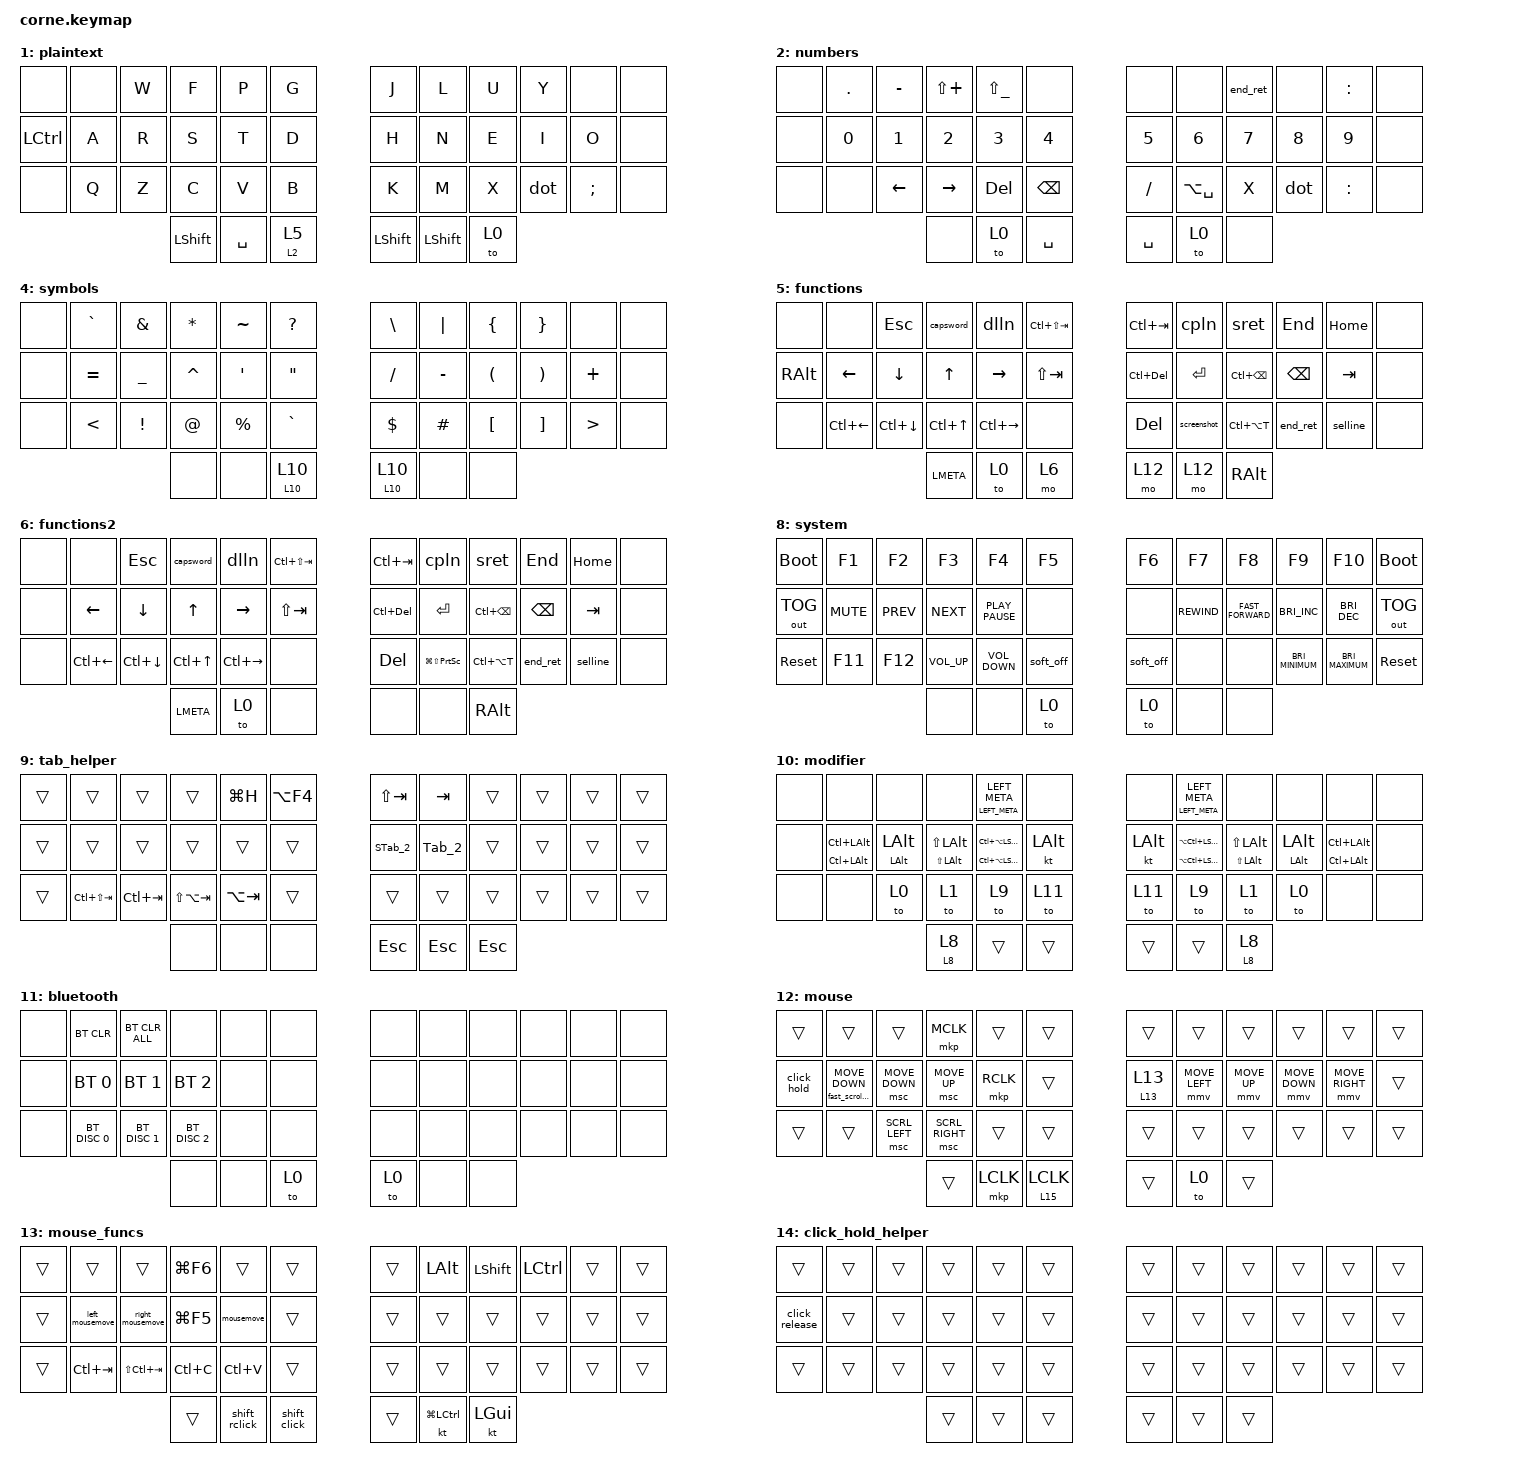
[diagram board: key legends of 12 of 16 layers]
/*
 * Copyright (c) 2020 The ZMK Contributors
 *
 * SPDX-License-Identifier: MIT
 */

#define ZMK_POINTING_DEFAULT_MOVE_VAL 1000  // default: 600
#define ZMK_POINTING_DEFAULT_SCRL_VAL 10   // default: 10

#include <input/processors.dtsi>
#include <behaviors.dtsi>
#include <dt-bindings/zmk/bt.h>
#include <dt-bindings/zmk/keys.h>
#include <dt-bindings/zmk/outputs.h>
#include <dt-bindings/zmk/pointing.h>

#define MAIN 0
#define NAV 1
#define SYM 2
#define FUNC 3
#define FUNC_2 4
#define QWERTY 5

&mmv_input_listener {
    input-processors = <&zip_xy_scaler 1 1>;

    slowMode {
        layers = <14>;
        input-processors = <&zip_xy_scaler 1 2>;
    };
};

/ {
    behaviors {
        dot: dot {
            compatible = "zmk,behavior-tap-dance";
            label = "DOT";
            #binding-cells = <0>;
            bindings = <&kp PERIOD>, <&kp COMMA>;
        };

        ht_lyr: ht_lyr {
            compatible = "zmk,behavior-hold-tap";
            label = "HT_LYR";
            bindings = <&mo>, <&sl>;

            #binding-cells = <2>;
            tapping-term-ms = <160>;
            flavor = "balanced";
            quick-tap-ms = <100>;
        };

        left_hrm: left_hrm {
            compatible = "zmk,behavior-hold-tap";
            label = "LEFT_HRM";
            #binding-cells = <2>;
            flavor = "balanced";
            tapping-term-ms = <160>;
            hold-trigger-key-positions = <6 7 8 9 10 11 18 19 20 21 22 23 30 31 32 33 34 35 39 40 41 36 37 38 0 12 24>;
            bindings = <&kp>, <&kp>;
        };

        right_hrm: right_hrm {
            compatible = "zmk,behavior-hold-tap";
            label = "RIGHT_HRM";
            bindings = <&kp>, <&kp>;

            #binding-cells = <2>;
            tapping-term-ms = <160>;
            flavor = "balanced";
            hold-trigger-key-positions = <0 1 2 3 4 5 12 13 14 15 16 17 24 25 26 27 28 29 36 37 38 39 40 41 11 23 35>;
        };

        left_hrm2: left_hrm2 {
            compatible = "zmk,behavior-hold-tap";
            label = "LEFT_HRM2";
            #binding-cells = <2>;
            flavor = "balanced";
            tapping-term-ms = <145>;
            hold-trigger-key-positions = <6 7 9 10 11 18 19 20 21 22 23 30 31 32 33 34 35 39 40 41 8 36 37 38 0 12 24>;
            bindings = <&mo>, <&kp>;
        };

        right_hrm2: right_hrm2 {
            compatible = "zmk,behavior-hold-tap";
            label = "RIGHT_HRM2";
            bindings = <&mo>, <&kp>;

            #binding-cells = <2>;
            tapping-term-ms = <145>;
            flavor = "balanced";
            hold-trigger-key-positions = <0 1 5 12 13 14 15 16 17 24 25 26 27 28 29 36 37 38 2 3 4 39 40 41 11 23 35>;
            quick-tap-ms = <0>;
        };

        ht_sk: ht_sk {
            compatible = "zmk,behavior-hold-tap";
            label = "HT_SK";
            bindings = <&kp>, <&sk>;

            #binding-cells = <2>;
            tapping-term-ms = <210>;
            flavor = "tap-preferred";
        };

        left_hrm_3: left_hrm_3 {
            compatible = "zmk,behavior-hold-tap";
            label = "LEFT_HRM_3";
            #binding-cells = <2>;
            flavor = "tap-preferred";
            tapping-term-ms = <185>;
            hold-trigger-key-positions = <6 7 8 9 10 11 18 19 20 21 22 23 30 31 32 33 34 35 39 40 41 36 37 38 0 12 24>;
            bindings = <&kp>, <&kp>;

            require-prior-idle-ms = <120>;
            hold-trigger-on-release;
        };

        right_hrm_3: right_hrm_3 {
            compatible = "zmk,behavior-hold-tap";
            label = "RIGHT_HRM_3";
            bindings = <&kp>, <&kp>;

            #binding-cells = <2>;
            tapping-term-ms = <185>;
            flavor = "tap-preferred";
            hold-trigger-key-positions = <0 1 2 3 4 5 12 13 14 15 16 17 24 25 26 27 28 29 36 37 38 39 40 41 11 23 35>;
            require-prior-idle-ms = <120>;
            hold-trigger-on-release;
        };

        caps_word1: caps_word1 {
            compatible = "zmk,behavior-caps-word";
            label = "CAPS_WORD1";
            #binding-cells = <0>;
            continue-list = <F22>;
            mods = <(MOD_LSFT)>;
        };

        ht_k_lyr: ht_k_lyr {
            compatible = "zmk,behavior-hold-tap";
            label = "HT_K_LYR";
            #binding-cells = <2>;
            flavor = "balanced";
            tapping-term-ms = <140>;
            bindings = <&mo>, <&kp>;

            require-prior-idle-ms = <70>;
            hold-trigger-on-release;
        };

        ht_mtab: ht_mtab {
            compatible = "zmk,behavior-hold-tap";
            label = "HT_MTAB";
            bindings = <&ht_lyr_mtab>, <&kp>;

            #binding-cells = <2>;
            tapping-term-ms = <200>;
            flavor = "tap-preferred";
        };

        ht_mkp_lyr: ht_mkp_lyr {
            compatible = "zmk,behavior-hold-tap";
            label = "HT_MKP_LYR";
            #binding-cells = <2>;
            flavor = "balanced";
            tapping-term-ms = <140>;
            bindings = <&mo>, <&mkp>;

            require-prior-idle-ms = <70>;
            hold-trigger-on-release;
        };

        fast_scroll_down: fast_scroll_down {
            compatible = "zmk,behavior-input-two-axis";
            label = "FAST_SCROLL_DOWN";
            #binding-cells = <1>;
            trigger-period-ms = <0>;
            x-input-code = <0>;
            y-input-code = <8>;
            delay-ms = <0>;
            time-to-max-speed-ms = <100>;
        };

        screenshot: screenshot {
            compatible = "zmk,behavior-tap-dance";
            label = "SCREENSHOT";
            #binding-cells = <0>;
            bindings = <&kp LS(LC(PRINTSCREEN))>, <&kp LC(LA(PRINTSCREEN))>;
        };
    };

    macros {
        sret: sret {
            compatible = "zmk,behavior-macro";
            #binding-cells = <0>;
            bindings = <&kp END &kp LS(RET)>;
            label = "SRET";
        };

        af4: af4 {
            compatible = "zmk,behavior-macro";
            #binding-cells = <0>;
            bindings = <&kt LEFT_ALT &kp F4 &kt LEFT_ALT>;
            label = "AF4";
        };

        end_ret: endRet {
            compatible = "zmk,behavior-macro";
            #binding-cells = <0>;
            bindings = <&kp END &kp RET>;
            label = "ENDRET";
        };

        cpln: cpln {
            compatible = "zmk,behavior-macro";
            #binding-cells = <0>;
            bindings = <&kp HOME &kp LS(END) &kp LC(C) &kp END>;
            label = "CPLN";
        };

        dlln: dlln {
            compatible = "zmk,behavior-macro";
            #binding-cells = <0>;
            bindings = <&kp HOME &kp LS(END) &kp DEL>;
            label = "DLLN";
        };

        sw1: sw1 {
            compatible = "zmk,behavior-macro";
            #binding-cells = <0>;
            bindings = <&kp LS(LG(LEFT_ARROW)) &kp LG(LA(H)) &kp LS(LG(RIGHT))>;
            label = "SW1";
        };

        sw2: sw2 {
            compatible = "zmk,behavior-macro";
            #binding-cells = <0>;
            bindings = <&kp LS(LG(RIGHT)) &kp LA(LG(H)) &kp LS(LG(LEFT_ARROW))>;
            label = "SW2";
        };

        capsword: capsword {
            compatible = "zmk,behavior-macro";
            #binding-cells = <0>;
            bindings = <&kp F22 &caps_word1>;
            label = "CAPSWORD";
        };

        on_MTab: on_MTab {
            compatible = "zmk,behavior-macro";
            #binding-cells = <0>;
            bindings = <&kt LEFT_META &tog 9 &kp TAB>;
            label = "ON_MTAB";
        };

        on_MSTab: on_MSTab {
            compatible = "zmk,behavior-macro";
            #binding-cells = <0>;
            bindings = <&kt LEFT_META &tog 9 &kp LS(TAB)>;
            label = "ON_MSTAB";
        };

        STab_2: STab_2 {
            compatible = "zmk,behavior-macro";
            #binding-cells = <0>;
            bindings = <&kp LS(TAB) &kp LS(TAB)>;
            label = "STAB_2";
        };

        Tab_2: Tab_2 {
            compatible = "zmk,behavior-macro";
            #binding-cells = <0>;
            bindings = <&kp TAB &kp TAB>;
            label = "TAB_2";
        };

        selline: selline {
            compatible = "zmk,behavior-macro";
            #binding-cells = <0>;
            bindings = <&kp HOME &kp HOME &kp LS(END) &kp LS(END)>;
            label = "SELLINE";
        };

        dlln2: dlln2 {
            compatible = "zmk,behavior-macro";
            #binding-cells = <0>;
            bindings = <&kp END &kp END &kp LS(LC(BACKSPACE))>;
            label = "DLLN2";
        };

        cut_line: cut_line {
            compatible = "zmk,behavior-macro";
            #binding-cells = <0>;
            bindings = <&kp HOME &kp HOME &kp LS(END) &kp LS(END) &kp LC(X)>;
            label = "CUT_LINE";
        };

        left_mousemove: left_mousemove {
            compatible = "zmk,behavior-macro";
            #binding-cells = <0>;
            bindings = <&kp LS(LG(LC(J))) &kp LG(F5)>;
            label = "LEFT_MOUSEMOVE";
        };

        right_mousemove: right_mousemove {
            compatible = "zmk,behavior-macro";
            #binding-cells = <0>;
            bindings = <&kp LS(LG(LC(H))) &kp LG(F5)>;
            label = "RIGHT_MOUSEMOVE";
        };

        mousemove: mousemove {
            compatible = "zmk,behavior-macro";
            #binding-cells = <0>;
            bindings = <&kp LG(LA(F)) &kp LG(F5)>;
            label = "MOUSEMOVE";
        };

        ht_lyr_mtab: ht_lyr_mtab {
            compatible = "zmk,behavior-macro";
            #binding-cells = <0>;
            bindings =
                <&to 3>,
                <&macro_pause_for_release>,
                <&macro_release>,
                <&kp LEFT_GUI>,
                <&macro_press>,
                <&to 0>;

            label = "HT_LYR_MTAB";
        };

        shift_click: shift_click {
            compatible = "zmk,behavior-macro";
            #binding-cells = <0>;
            bindings =
                <&macro_press>,
                <&kp LSHFT>,
                <&macro_tap>,
                <&mkp LCLK>,
                <&macro_release>,
                <&kp LSHFT>;

            label = "SHIFT_CLICK";
        };

        shift_rclick: shift_rclick {
            compatible = "zmk,behavior-macro";
            #binding-cells = <0>;
            bindings =
                <&macro_press>,
                <&kp LSHFT>,
                <&macro_tap>,
                <&mkp RCLK>,
                <&macro_release>,
                <&kp LSHFT>;

            label = "SHIFT_RCLICK";
        };

        click_hold: click_hold {
            compatible = "zmk,behavior-macro";
            #binding-cells = <0>;
            bindings = <&tog 14>, <&macro_press>, <&mkp LCLK>;

            label = "CLICK_HOLD";
        };

        click_release: click_release {
            compatible = "zmk,behavior-macro";
            #binding-cells = <0>;
            bindings = <&tog 14>, <&macro_release>, <&mkp LCLK>;

            label = "CLICK_RELEASE";
        };

        on_MTab_2: on_Mtab_2 {
            compatible = "zmk,behavior-macro";
            #binding-cells = <0>;
            bindings = <&kt LEFT_META &tog 9 &kp LC(TAB)>;
            label = "ON_MTAB_2";
        };

        on_MSTab_2: on_MSTab_2 {
            compatible = "zmk,behavior-macro";
            #binding-cells = <0>;
            bindings = <&kt LEFT_META &tog 9 &kp LC(LS(TAB))>;
            label = "ON_MSTAB_2";
        };

        on_MTab_3: on_MTab_3 {
            compatible = "zmk,behavior-macro";
            #binding-cells = <0>;
            bindings = <&kt LEFT_META &tog 9 &kp LA(TAB)>;
            label = "ON_MTAB_3";
        };

        on_MSTab_3: on_MSTab_3 {
            compatible = "zmk,behavior-macro";
            #binding-cells = <0>;
            bindings = <&kt LEFT_META &tog 9 &kp LA(LS(TAB))>;
            label = "ON_MSTAB_3";
        };

        moveMonRight: moveMonRight {
            compatible = "zmk,behavior-macro";
            #binding-cells = <0>;
            bindings = <&kp LG(LS(RIGHT))>;
            label = "MOVEMONRIGHT";
        };

        moveMonLeft: moveMonLeft {
            compatible = "zmk,behavior-macro";
            #binding-cells = <0>;
            bindings = <&kp LG(LS(LEFT))>;
            label = "MOVEMONLEFT";
        };

        moveWsNext: moveWsNext {
            compatible = "zmk,behavior-macro";
            #binding-cells = <0>;
            bindings = <&kp LG(LS(LC(RIGHT)))>;
            label = "MOVEWSNEXT";
        };

        moveWsPrev: moveWsPrev {
            compatible = "zmk,behavior-macro";
            #binding-cells = <0>;
            bindings = <&kp LG(LS(LC(LEFT)))>;
            label = "MOVEWSPREV";
        };

        focusWsNext: focusWsNext {
            compatible = "zmk,behavior-macro";
            #binding-cells = <0>;
            bindings = <&kp LC(LG(RIGHT))>;
            label = "FOCUSWSNEXT";
        };

        focusWsPrev: focusWsPrev {
            compatible = "zmk,behavior-macro";
            #binding-cells = <0>;
            bindings = <&kp LC(LG(LEFT))>;
            label = "FOCUSWSPREV";
        };

        focusMonNext: focusMonNext {
            compatible = "zmk,behavior-macro";
            #binding-cells = <0>;
            bindings = <&kp LC(LG(LS(H)))>;
            label = "FOCUSMONNEXT";
        };

        focusMonPrev: focusMonPrev {
            compatible = "zmk,behavior-macro";
            #binding-cells = <0>;
            bindings = <&kp LC(LG(LS(J)))>;
            label = "FOCUSMONPREV";
        };

        cycleFocus: cycleFocus {
            compatible = "zmk,behavior-macro";
            #binding-cells = <0>;
            bindings = <&kp LA(LG(H))>;
            label = "CYCLEFOCUS";
        };

        moveWsUp: moveWsUp {
            compatible = "zmk,behavior-macro";
            #binding-cells = <0>;
            bindings = <&kp LG(LS(LC(UP)))>;
            label = "MOVEWSUP";
        };

        moveWsDown: moveWsDown {
            compatible = "zmk,behavior-macro";
            #binding-cells = <0>;
            bindings = <&kp LG(LS(LC(DOWN)))>;
            label = "MOVEWSDOWN";
        };

        focusWsUp: focusWsUp {
            compatible = "zmk,behavior-macro";
            #binding-cells = <0>;
            bindings = <&kp LC(LG(UP))>;
            label = "FOCUSWSUP";
        };

        focusWsDown: focusWsDown {
            compatible = "zmk,behavior-macro";
            #binding-cells = <0>;
            bindings = <&kp LC(LG(DOWN))>;
            label = "FOCUSWSDOWN";
        };

        overlay: new_macro {
            compatible = "zmk,behavior-macro";
            #binding-cells = <0>;
            bindings =
                <&macro_tap>,
                <&kp LG(LA(O))>,
                <&macro_pause_for_release>,
                <&kp LG(LS(O))>;

            label = "NEW_MACRO";
        };
    };

    combos {
        compatible = "zmk,combos";

        cut {
            bindings = <&cut_line>;
            key-positions = <4 7>;
            layers = <6>;
        };
    };

    keymap {
        compatible = "zmk,keymap";

        default_layer {
            bindings = <
&kp LS(LC(LG(D)))  &none  &kp W           &kp F                &kp P              &kp G          &kp J        &kp L               &kp U                 &kp Y            &none          &kp RCTRL
&overlay           &kp A  &left_hrm2 4 R  &left_hrm_3 LCTRL S  &left_hrm LSHFT T  &kp D          &kp H        &right_hrm LSHFT N  &right_hrm_3 LCTRL E  &right_hrm2 4 I  &kp O          &kp RALT
&kp LEFT_GUI       &kp Q  &kp Z           &kp C                &kp V              &kp B          &kp K        &kp M               &kp X                 &dot             &kp SEMICOLON  &kp LEFT_GUI
                                          &ht_lyr 10 10        &ht_k_lyr 7 SPACE  &ht_lyr 2 5    &ht_lyr 2 5  &ht_mtab 0 SPACE    &ht_lyr 7 7
            >;
        };

        plaintext {
            bindings = <
&none      &none  &kp W  &kp F      &kp P      &kp G          &kp J           &kp L      &kp U  &kp Y  &none          &none
&kp LCTRL  &kp A  &kp R  &kp S      &kp T      &kp D          &kp H           &kp N      &kp E  &kp I  &kp O          &none
&none      &kp Q  &kp Z  &kp C      &kp V      &kp B          &kp K           &kp M      &kp X  &dot   &kp SEMICOLON  &none
                         &kp LSHFT  &kp SPACE  &ht_lyr 2 5    &kp LEFT_SHIFT  &kp LSHFT  &to 0
            >;
        };

        numbers {
            // -----------------------------------------------------------------------------------------
            // |  TAB |  1  |  2  |  3  |  4  |  5  |   |  6  |  7  |  8  |  9  |  0  | BSPC |
            // | BTCLR| BT1 | BT2 | BT3 | BT4 | BT5 |   | LFT | DWN |  UP | RGT |     |      |
            // | SHFT |     |     |     |     |     |   |     |     |     |     |     |      |
            //                    | GUI |     | SPC |   | ENT |     | ALT |

            bindings = <
&none  &kp DOT  &kp MINUS       &kp LS(PLUS)  &kp LS(UNDER)  &none            &none      &none          &end_ret  &none   &kp COLON  &none
&none  &kp N0   &kp N1          &kp N2        &kp N3         &kp N4           &kp N5     &kp N6         &kp N7    &kp N8  &kp N9     &none
&none  &none    &kp LEFT_ARROW  &kp RIGHT     &kp DELETE     &kp BACKSPACE    &kp FSLH   &kp LA(SPACE)  &kp X     &dot    &kp COLON  &none
                                &none         &to 0          &kp SPACE        &kp SPACE  &to 0          &none
            >;
        };

        navigation {
            bindings = <
&none  &none          &kp LG(LC(LS(T)))  &kp LG(LC(LS(Q)))  &kp LG(RET)   &kp LA(F4)    &kp LC(END)  &kp LC(HOME)  &kp LG(H)     &kp LG(F)     &none          &none
&none  &focusMonPrev  &focusMonNext      &kp LG(LA(J))      &cycleFocus   &moveWsUp     &moveWsDown  &focusWsPrev  &focusWsNext  &moveMonLeft  &moveMonRight  &none
&none  &kp LG(N0)     &kp LG(N1)         &focusWsUp         &focusWsDown  &kp LG(F5)    &kp LG(F6)   &moveWsPrev   &moveWsNext   &kp LC(END)   &kp LC(HOME)   &none
                                         &none              &none         &none         &none        &none         &none
            >;
        };

        symbols {
            bindings = <
&none  &kp GRAVE      &kp AMPERSAND    &kp ASTRK  &kp TILDE       &kp QUESTION         &kp BSLH       &kp PIPE   &kp LEFT_BRACE        &kp RIGHT_BRACE        &none             &none
&none  &kp EQUAL      &kp UNDER        &kp CARET  &kp APOSTROPHE  &kp DOUBLE_QUOTES    &kp SLASH      &kp MINUS  &kp LEFT_PARENTHESIS  &kp RIGHT_PARENTHESIS  &kp PLUS          &none
&none  &kp LESS_THAN  &kp EXCLAMATION  &kp AT     &kp PERCENT     &kp GRAVE            &kp DOLLAR     &kp HASH   &kp LBKT              &kp RBKT               &kp GREATER_THAN  &none
                                       &none      &none           &ht_lyr 10 10        &ht_lyr 10 10  &none      &none
            >;
        };

        functions {
            bindings = <
&none     &none         &kp ESC         &capsword     &dlln          &kp LC(LS(TAB))    &kp LC(TAB)     &cpln        &sret          &kp END   &kp HOME  &none
&kp RALT  &kp LEFT      &kp DOWN_ARROW  &kp UP_ARROW  &kp RIGHT      &kp LS(TAB)        &kp LC(DELETE)  &kp RET      &kp LC(BSPC)   &kp BSPC  &kp TAB   &none
&none     &kp LC(LEFT)  &kp LC(DOWN)    &kp LC(UP)    &kp LC(RIGHT)  &none              &kp DELETE      &screenshot  &kp LC(LA(T))  &end_ret  &selline  &none
                                        &kp LMETA     &to 0          &mo 6              &mo 12          &mo 12       &kp RALT
            >;
        };

        functions2 {
            bindings = <
&none  &none         &kp ESC         &capsword     &dlln          &kp LC(LS(TAB))    &kp LC(TAB)  &cpln                    &sret          &kp END   &kp HOME  &none
&none  &kp LEFT      &kp DOWN_ARROW  &kp UP_ARROW  &kp RIGHT      &kp LS(TAB)        &kp LC(DEL)  &kp RET                  &kp LC(BSPC)   &kp BSPC  &kp TAB   &none
&none  &kp LC(LEFT)  &kp LC(DOWN)    &kp LC(UP)    &kp LC(RIGHT)  &none              &kp DELETE   &kp LG(LS(PRINTSCREEN))  &kp LC(LA(T))  &end_ret  &selline  &none
                                     &kp LMETA     &to 0          &none              &none        &none                    &kp RALT
            >;
        };

        in_app_functions {
            bindings = <
&none  &kp LS(LA(LC(F10)))       &kp LS(LA(LC(F1)))        &kp LA(LC(LS(F2)))        &kp LS(LA(LC(F3)))        &kp LS(LA(LC(F4)))          &kp LS(LA(LC(F5)))        &kp LS(LA(LC(F6)))        &kp LS(LA(LC(F7)))     &kp LS(LC(LA(F8)))     &kp LS(LC(LA(F9)))    &none
&none  &kp LS(LC(LA(NUMBER_0)))  &kp LS(LA(LC(NUMBER_1)))  &kp LS(LA(LC(NUMBER_2)))  &kp LS(LC(LA(NUMBER_3)))  &kp LS(LA(LC(NUMBER_4)))    &kp LS(LA(LC(NUMBER_5)))  &kp LS(LC(LA(NUMBER_6)))  &kp LC(LA(LS(N7)))     &kp LS(LC(LA(N8)))     &kp LC(LA(LS(N9)))    &none
&none  &kp LA(LC(LS(COMMA)))     &kp LS(LA(LC(DOT)))       &kp LS(LC(LA(FSLH)))      &kp LS(LA(LC(APOS)))      &kp LS(LC(LA(SEMI)))        &kp LS(LA(LC(LBKT)))      &kp LS(LA(LC(RBKT)))      &kp LS(LC(LA(MINUS)))  &kp LS(LA(LC(EQUAL)))  &kp LS(LA(LC(BSLH)))  &none
                                                           &ht_lyr 10 10             &none                     &none                       &none                     &none                     &ht_lyr 10 10
            >;
        };

        system {
            bindings = <
&bootloader   &kp F1      &kp F2      &kp F3           &kp F4             &kp F5       &kp F6     &kp F7        &kp F8              &kp F9                    &kp F10                   &bootloader
&out OUT_TOG  &kp K_MUTE  &kp K_PREV  &kp K_NEXT       &kp K_PLAY_PAUSE   &none        &none      &kp C_REWIND  &kp C_FAST_FORWARD  &kp C_BRIGHTNESS_INC      &kp C_BRIGHTNESS_DEC      &out OUT_TOG
&sys_reset    &kp F11     &kp F12     &kp C_VOLUME_UP  &kp C_VOLUME_DOWN  &soft_off    &soft_off  &none         &none               &kp C_BRIGHTNESS_MINIMUM  &kp C_BRIGHTNESS_MAXIMUM  &sys_reset
                                      &none            &none              &to 0        &to 0      &none         &none
            >;
        };

        tab_helper {
            bindings = <
&trans  &trans           &trans       &trans           &kp LG(H)    &kp LA(F4)    &kp LS(TAB)  &kp TAB  &trans   &trans  &trans  &trans
&trans  &trans           &trans       &trans           &trans       &trans        &STab_2      &Tab_2   &trans   &trans  &trans  &trans
&trans  &kp LC(LS(TAB))  &kp LC(TAB)  &kp LS(LA(TAB))  &kp LA(TAB)  &trans        &trans       &trans   &trans   &trans  &trans  &trans
                                      &none            &none        &none         &kp ESC      &kp ESC  &kp ESC
            >;
        };

        modifier {
            bindings = <
&none  &none                             &none             &none                             &ht_sk LEFT_META LEFT_META          &none           &none         &ht_sk LEFT_META LEFT_META           &none                             &none                 &none                             &none
&none  &ht_sk LC(LEFT_ALT) LC(LEFT_ALT)  &ht_sk LALT LALT  &ht_sk LS(LEFT_ALT) LS(LEFT_ALT)  &ht_sk LC(LA(LSHFT)) LC(LA(LSHFT))  &kt LEFT_ALT    &kt LEFT_ALT  &ht_sk LA(LC(LSHFT)) LA(LC(LSHIFT))  &ht_sk LS(LEFT_ALT) LS(LEFT_ALT)  &ht_sk LEFT_ALT LALT  &ht_sk LC(LEFT_ALT) LC(LEFT_ALT)  &none
&none  &none                             &to 0             &to 1                             &to 9                               &to 11          &to 11        &to 9                                &to 1                             &to 0                 &none                             &none
                                                           &ht_lyr 8 8                       &trans                              &trans          &trans        &trans                               &ht_lyr 8 8
            >;
        };

        bluetooth {
            bindings = <
&none  &bt BT_CLR     &bt BT_CLR_ALL  &none          &none  &none    &none  &none  &none  &none  &none  &none
&none  &bt BT_SEL 0   &bt BT_SEL 1    &bt BT_SEL 2   &none  &none    &none  &none  &none  &none  &none  &none
&none  &bt BT_DISC 0  &bt BT_DISC 1   &bt BT_DISC 2  &none  &none    &none  &none  &none  &none  &none  &none
                                      &none          &none  &to 0    &to 0  &none  &none
            >;
        };

        mouse {
            bindings = <
&trans       &trans                       &trans          &mkp MCLK        &trans     &trans                 &trans         &trans          &trans        &trans          &trans           &trans
&click_hold  &fast_scroll_down MOVE_DOWN  &msc MOVE_DOWN  &msc MOVE_UP     &mkp RCLK  &trans                 &ht_lyr 13 13  &mmv MOVE_LEFT  &mmv MOVE_UP  &mmv MOVE_DOWN  &mmv MOVE_RIGHT  &trans
&trans       &trans                       &msc SCRL_LEFT  &msc SCRL_RIGHT  &trans     &trans                 &trans         &trans          &trans        &trans          &trans           &trans
                                                          &trans           &mkp LCLK  &ht_mkp_lyr 15 LCLK    &trans         &to 0           &trans
            >;
        };

        mouse_funcs {
            bindings = <
&trans  &trans           &trans            &kp LG(F6)  &trans         &trans          &trans  &kp LALT       &kp LSHFT  &kp LCTRL  &trans  &trans
&trans  &left_mousemove  &right_mousemove  &kp LG(F5)  &mousemove     &trans          &trans  &trans         &trans     &trans     &trans  &trans
&trans  &kp LC(TAB)      &kp LS(LC(TAB))   &kp LC(C)   &kp LC(V)      &trans          &trans  &trans         &trans     &trans     &trans  &trans
                                           &trans      &shift_rclick  &shift_click    &trans  &kt LG(LCTRL)  &kt LGUI
            >;
        };

        click_hold_helper {
            bindings = <
&trans          &trans  &trans  &trans  &trans  &trans    &trans  &trans  &trans  &trans  &trans  &trans
&click_release  &trans  &trans  &trans  &trans  &trans    &trans  &trans  &trans  &trans  &trans  &trans
&trans          &trans  &trans  &trans  &trans  &trans    &trans  &trans  &trans  &trans  &trans  &trans
                                &trans  &trans  &trans    &trans  &trans  &trans
            >;
        };

        mouse_slow {
            bindings = <
&trans  &trans  &trans  &trans  &trans  &trans    &trans  &trans  &trans  &trans  &trans  &trans
&trans  &trans  &trans  &trans  &trans  &trans    &trans  &trans  &trans  &trans  &trans  &trans
&trans  &trans  &trans  &trans  &trans  &trans    &trans  &trans  &trans  &trans  &trans  &trans
                        &trans  &trans  &trans    &trans  &trans  &trans
            >;
        };
    };

    conditional_layers { compatible = "zmk,conditional-layers"; };
};
